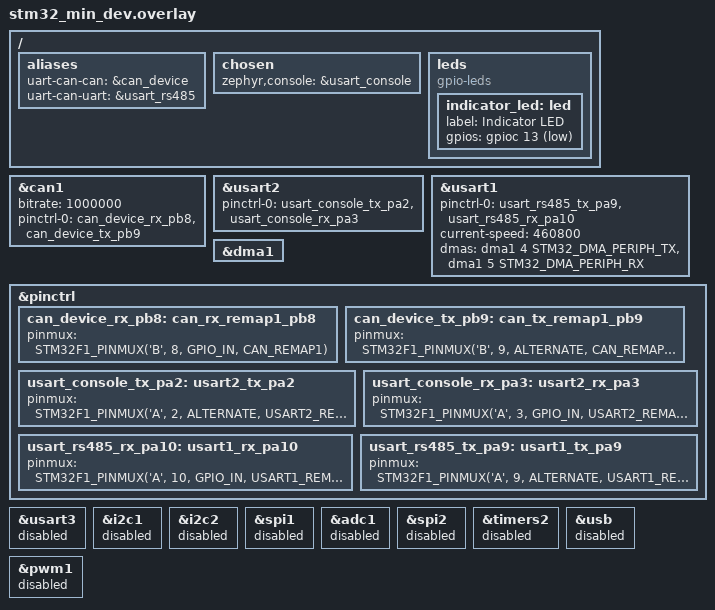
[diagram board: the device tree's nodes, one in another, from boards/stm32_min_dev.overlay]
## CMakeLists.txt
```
# SPDX-License-Identifier: Apache-2.0

cmake_minimum_required(VERSION 3.20.0)


find_package(Zephyr REQUIRED HINTS $ENV{ZEPHYR_BASE})
project(uart_to_can)

set(UART_TO_CAN_SRC
    ${CMAKE_CURRENT_SOURCE_DIR}/src/main.c
    ${CMAKE_CURRENT_SOURCE_DIR}/src/uart_to_can.c
    ${CMAKE_CURRENT_SOURCE_DIR}/src/uart_to_can_core_utility.c
)
target_sources(app PRIVATE ${UART_TO_CAN_SRC})
target_include_directories(app PRIVATE ${CMAKE_CURRENT_SOURCE_DIR}/include)
target_compile_options(app PRIVATE -Werror -Wall -Wextra -Wshadow -Wdouble-promotion -Wformat -Wunused)
target_link_libraries(app PRIVATE)
```

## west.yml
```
manifest:
  # lowest version of the manifest file schema that can parse this file’s data
  version: 1.2

  projects:
      - name: zephyr
        # instead of a tag, `revision` also supports hashes and branches. e.g., `--freeze` will
        # replace all revisions with their aactual commit hashes since tags can always be modified.
        revision: v4.4.0
        url: https://github.com/zephyrproject-rtos/zephyr
        # explicitly adding Zephyr-specific West extensions is only needed in case no `import`s are
        # used - which is almost never the case for Zephyr applications. with `import` in place,
        # the `west.yml` in Zephyr's repository takes care of adding the required West extensions.
        west-commands: scripts/west-commands.yml
        import:
          path-prefix: west_deps
        # # defaults to west.yml, but added for good measure/demonstration purposes.
        # file: west.yml
          name-allowlist:
            - cmsis
            - cmsis_6
            - hal_st
            - hal_stm32
            - hal_rpi_pico
```

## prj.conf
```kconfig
## Printing
# CONFIG_LOG=y
# # CONFIG_LOG_MODE_IMMEDIATE=y
# CONFIG_PRINTK=y
# CONFIG_LOG_DEFAULT_LEVEL=2

# CONFIG_THREAD_NAME=y
# CONFIG_ASSERT=y
# Peripherals

# UART
CONFIG_SERIAL=y
CONFIG_UART_ASYNC_API=y
CONFIG_UART_USE_RUNTIME_CONFIGURE=y

# CAN
CONFIG_CAN=y
CONFIG_CAN_STM32_BXCAN_MAX_STD_ID_FILTERS=4
CONFIG_CAN_STM32_BXCAN_MAX_EXT_ID_FILTERS=12

# Stacks size
CONFIG_ISR_STACK_SIZE=1024
CONFIG_MAIN_STACK_SIZE=2048
CONFIG_SYSTEM_WORKQUEUE_STACK_SIZE=4096

CONFIG_SYSTEM_WORKQUEUE_PRIORITY=-1

# CONFIG_KERNEL_MEM_POOL=y

# Debug options
# CONFIG_DEBUG_OPTIMIZATIONS=y
# CONFIG_NO_OPTIMIZATIONS=y
# CONFIG_BOOT_BANNER is not set
# CONFIG_EXCEPTION_DEBUG=y
CONFIG_STM32_ENABLE_DEBUG_SLEEP_STOP=y
```

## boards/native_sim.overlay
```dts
/ {
	aliases {
		uart-can-can = &can_device;
		uart-can-uart = &usart_rs485;
	};

	chosen{
		zephyr,console = &usart_console;

	};


	leds {
		compatible = "gpio-leds";
		status = "okay";
		indicator_led: indicator_led {
			label = "Indicator LED";
			gpios = <&gpio0 13 GPIO_ACTIVE_LOW>;
		};
	};
};

can_device: &can_loopback0 {
	status = "okay";
	bitrate = <250000>;
};

usart_console: &uart0 {
	status = "okay";
};


usart_rs485: &uart1 {
	status = "okay";
	current-speed = <115200>;
};
```

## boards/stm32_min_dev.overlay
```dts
/ {
	aliases {
		uart-can-can = &can_device;
		uart-can-uart = &usart_rs485;
	};

	chosen {
		zephyr,console = &usart_console;
	};

	leds {
		compatible = "gpio-leds";
		status = "okay";

		indicator_led: led {
			label = "Indicator LED";
			gpios = <&gpioc 13 GPIO_ACTIVE_LOW>;
		};
	};
};

can_device: &can1 {
	status = "okay";
	bitrate = <1000000>;
	pinctrl-0 = <&can_device_rx_pb8 &can_device_tx_pb9>;
	pinctrl-names = "default";
};

usart_console: &usart2 {
	status = "okay";
	pinctrl-0 = <&usart_console_tx_pa2 &usart_console_rx_pa3>;
	pinctrl-names = "default";
};

usart_rs485: &usart1 {
	status = "okay";
	pinctrl-0 = <&usart_rs485_tx_pa9 &usart_rs485_rx_pa10>;
	pinctrl-names = "default";
	current-speed = <460800>;
	/* Format: <&dma_controller_phandle channel channel_config> */
	dmas = <&dma1 4 STM32_DMA_PERIPH_TX>,  /* USART1_TX is fixed to Channel 4 */
	       <&dma1 5 STM32_DMA_PERIPH_RX>;  /* USART1_RX is fixed to Channel 5 */
	dma-names = "tx", "rx";
};

/* 1. Ensure the global DMA engine is turned on */
&dma1 {
	status = "okay";
};

&pinctrl {
	// swj-cfg = "full";

	can_device_rx_pb8: can_rx_remap1_pb8 {
		pinmux = <STM32F1_PINMUX('B', 8, GPIO_IN, CAN_REMAP1)>;
	};

	can_device_tx_pb9: can_tx_remap1_pb9 {
		pinmux = <STM32F1_PINMUX('B', 9, ALTERNATE, CAN_REMAP1)>;
	};

	usart_console_tx_pa2: usart2_tx_pa2 {
		pinmux = <STM32F1_PINMUX('A', 2, ALTERNATE, USART2_REMAP0)>;
	};

	usart_console_rx_pa3: usart2_rx_pa3 {
		pinmux = <STM32F1_PINMUX('A', 3, GPIO_IN, USART2_REMAP0)>;
	};

	usart_rs485_rx_pa10: usart1_rx_pa10 {
		pinmux = <STM32F1_PINMUX('A', 10, GPIO_IN, USART1_REMAP0)>;
	};

	usart_rs485_tx_pa9: usart1_tx_pa9 {
		pinmux = <STM32F1_PINMUX('A', 9, ALTERNATE, USART1_REMAP0)>;
	};
};


&usart3 {
	status = "disabled";
};

&i2c1 {
	status = "disabled";
};

&i2c2 {
	status = "disabled";
};

&spi1 {
	status = "disabled";
};

&adc1 {
	status = "disabled";
};

&spi2 {
	status = "disabled";
};

&timers2 {
	status = "disabled";
};

&usb {
	status = "disabled";
};

&pwm1 {
	status = "disabled";
};
```

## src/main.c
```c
#include "uart_to_can.h"

#include <zephyr/device.h>
#include <zephyr/devicetree.h>
#include <zephyr/drivers/can.h>
#include <zephyr/drivers/gpio.h>
#include <zephyr/kernel.h>
#include <zephyr/logging/log.h>

#include <zephyr/drivers/uart.h>

LOG_MODULE_REGISTER(main, LOG_LEVEL_INF);

#define LED0_NODE DT_ALIAS(led0)
static const struct gpio_dt_spec led = GPIO_DT_SPEC_GET(LED0_NODE, gpios);
int main(void)
{

  int err;
  err = init_uart_to_can();
  if (err < 0)
  {
    LOG_ERR("Failed to init uart to can");
    return 0;
  }

  if (!gpio_is_ready_dt(&led))
  {
    LOG_ERR("LED not ready");
  }

  err = gpio_pin_configure_dt(&led, GPIO_OUTPUT_ACTIVE);
  if (err < 0)
  {
    LOG_WRN("Failed to indicator LED");
  }

  while (1)
  {

    err = gpio_pin_toggle_dt(&led);
    k_msleep(2000);
  }
}
```

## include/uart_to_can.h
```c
#ifndef __UART_TO_CAN_H__
#define __UART_TO_CAN_H__

#include <stddef.h>
#include <stdint.h>
#include <zephyr/device.h>
#include <zephyr/drivers/uart.h>

#include "uart_to_can_core_utility.h"
/* Enum definition from supported commands. */
enum UART_CAN_COMMANDS
{
  UART_CAN_COMMANDS_START_CAN = 'O',
  UART_CAN_COMMANDS_STOP_CAN = 'C',
  UART_CAN_COMMANDS_SET_BITRATE = 'S',
  UART_CAN_COMMANDS_SEND_11_BIT_CAN = 't',
  UART_CAN_COMMANDS_SEND_29_BIT_CAN = 'T',
  UART_CAN_COMMANDS_VERSION = 'V',
  UART_CAN_COMMANDS_HELP = 'h',
  UART_CAN_COMMANDS_RESET = 'L',
  UART_CAN_COMMANDS_GET_STATE = 'G',
  UART_CAN_COMMANDS_ADD_FILTER_11_BIT = 'm',
  UART_CAN_COMMANDS_ADD_FILTER_29_BIT = 'M',
  UART_CAN_COMMANDS_REMOVE_FILTER = 'f',
  UART_CAN_COMMANDS_REMOVE_ALL_FILTERS = 'F',
};

/**
 * @brief Initialize the UART to CAN module.
 *
 * @return 0 if successful, <0 on error.
 */
int init_uart_to_can(void);
#endif /* __UART_TO_CAN_H__ */
```

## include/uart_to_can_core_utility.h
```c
#ifndef __UART_TO_CAN_CORE_UTILITY_H__
#define __UART_TO_CAN_CORE_UTILITY_H__

#include <assert.h>
#include <stdlib.h>
#include <stdio.h>
#include <zephyr/device.h>
#include <zephyr/drivers/can.h>
#include <zephyr/sys/ring_buffer.h>

#define HARDWARE_VERSION_MAJOR 0
#define HARDWARE_VERSION_MINOR 1

#define SOFTWARE_VERSION_MAJOR 0
#define SOFTWARE_VERSION_MINOR 1

#define CAN_ID_11_BIT_BYTE_LENGHT 3
#define CAN_ID_29_BIT_BYTE_LENGHT 8
#define CAN_FILTER_BYTE_LENGHT (8 + 8)
#define MESSAGE_BASE 16
#define COMMAND_RESPONSE_OKAY "\r"
#define COMMAND_RESPONSE_ERROR "\a"

#define FULL_VERSION_RESPONSE       \
  STRINGIFY(HARDWARE_VERSION_MAJOR) \
  STRINGIFY(HARDWARE_VERSION_MINOR) \
  STRINGIFY(SOFTWARE_VERSION_MAJOR) \
  STRINGIFY(SOFTWARE_VERSION_MINOR) \
  COMMAND_RESPONSE_OKAY

#define MAX_UART_CAN_FRAME \
  (1 + CAN_ID_29_BIT_BYTE_LENGHT + 2 + 1 + CAN_MAX_DLEN * 2 + 1)

#if defined(CONFIG_CAN_STM32_BXCAN_MAX_STD_ID_FILTERS)
#define CONFIG_CAN_MAX_STD_ID_FILTERS CONFIG_CAN_STM32_BXCAN_MAX_STD_ID_FILTERS
#else
#define CONFIG_CAN_MAX_STD_ID_FILTERS 5
#endif

#if defined(CONFIG_CAN_STM32_BXCAN_MAX_EXT_ID_FILTERS)
#define CONFIG_CAN_MAX_EXT_ID_FILTERS CONFIG_CAN_STM32_BXCAN_MAX_EXT_ID_FILTERS
#else
#define CONFIG_CAN_MAX_EXT_ID_FILTERS 5
#endif

struct uart_message
{
  void *fifo_reserved; /* 1st word reserved for use by FIFO */
  uint8_t buffer[MAX_UART_CAN_FRAME];
  size_t buffer_size;
};

static inline struct uart_message string_to_uart_message(const char *string)
{
  struct uart_message uart_message;
  uart_message.buffer_size = strlen(string);
  assert((size_t)snprintf(uart_message.buffer, MAX_UART_CAN_FRAME, "%s",
                          string) == uart_message.buffer_size);
  return uart_message;
}

/**
 * @brief Return the next byte in the ring buffer, this function assume that you
 * are sure that data is in the buffer, it asserts if the buffer is empty
 * @param buf Pointer to the ring buffer
 * @return the next byte in the ring buffer
 */
static inline uint8_t ring_buf_get_char(struct ring_buf *buf)
{
  uint8_t data;
  assert(ring_buf_get(buf, &data, 1) == 1);
  return data;
}

static inline bool ring_buf_get_char_to_uint(struct ring_buf *buf,
                                             uint8_t num_of_bytes, int base,
                                             unsigned long *out_val)
{
  char data[num_of_bytes + 1];
  char *temp_data;
  unsigned long temp_val;
  for (uint32_t i = 0; i < num_of_bytes; i++)
  {
    data[i] = ring_buf_get_char(buf);
  }
  data[num_of_bytes] = '\0';
  temp_val = strtoul(data, &temp_data, base);

  if ((uintptr_t)temp_data != (uintptr_t)data)
  {
    *out_val = temp_val;
    return true;
  }
  return false;
}

static inline bool ring_buf_get_hex_to_uint8_t(struct ring_buf *buf,
                                               uint8_t *out_val)
{
  char data[2 + 1];
  char *temp_data;
  unsigned long temp_val;
  for (uint32_t i = 0; i < 2; i++)
  {
    data[i] = ring_buf_get_char(buf);
  }
  data[2] = '\0';
  temp_val = strtoul(data, &temp_data, 16);

  if ((uintptr_t)temp_data != (uintptr_t)data)
  {
    *out_val = temp_val;
    return true;
  }
  return false;
}

static inline bool ring_buf_get_hex_to_uint32_t(struct ring_buf *buf,
                                                uint32_t *out_val)
{
  char data[8 + 1];
  char *temp_data;
  unsigned long temp_val;
  for (uint32_t i = 0; i < 8; i++)
  {
    data[i] = ring_buf_get_char(buf);
  }
  data[8] = '\0';
  temp_val = strtoul(data, &temp_data, 16);

  if ((uintptr_t)temp_data != (uintptr_t)data)
  {
    *out_val = temp_val;
    return true;
  }
  return false;
}
/**
 * @brief Checks if the ring buffer has wrapped
 *
 * @param buf Pointer to the ring buffer
 * @return true if the ring buffer has wrapped, false otherwise
 */
bool ring_buf_has_wrapped(struct ring_buf *buf);

/**
 * @brief Starts the CAN device
 *
 * @param can_dev Pointer to the CAN device
 * @return 0 on success, negative error code on failure
 */
int start_can_device(const struct device *can_dev);

/**
 * @brief Stops the CAN device
 *
 * @param can_dev Pointer to the CAN device
 * @return 0 on success, negative error code on failure
 */
int stop_can_device(const struct device *can_dev);

/**
 * @brief Sets the bitrate for the CAN device
 *
 * @param can_dev Pointer to the CAN device
 * @param bitrate_code uint8_t the encoded value of the bitrate
 * @return 0 on success, negative error code on failure
 */
int set_bitrate(const struct device *can_dev, uint8_t bitrate_code);

/**
 * @brief Adds a filter to the CAN device
 *
 * @param can_dev Pointer to the CAN device
 * @param filter_id The filter ID
 * @param filter_mask The filter mask
 * @param is_extended_id Whether the filter is for an extended ID
 * @return 0 on success, negative error code on failure
 */
int add_can_filter(const struct device *can_dev, uint32_t filter_id,
                   uint32_t filter_mask, bool is_extended_id);

/**
 * @brief Sends a message to the CAN bus
 *
 * @param can_dev Pointer to the CAN device
 * @param addr The CAN ID of the message
 * @param data Pointer to the data to send
 * @param data_size The size of the data to send
 * @param is_extended_id Whether the message is an extended ID
 * @param is_rtr Whether the message is an remote data
 * @return true if the message was sent successfully, false otherwise
 */
int send_can_message_no_wait(const struct device *can_dev, uint32_t addr,
                             const uint8_t data[], uint8_t data_size,
                             bool is_extended_id, bool is_rtr);

/**
 * @brief Searches for '\r' in the ring buffer, considering wrap-around
 *
 * @param buf Pointer to the ring buffer
 * @return The index of '\r' if found (positive index) or if wrap around
 *         occured (negative index), INT_MIN otherwise
 */
int search_r_consider_wrap(struct ring_buf *buf);

int send_command_status_via_uart(struct uart_message *message);

/**
@breif Clear all the character in a ring buffer before the char '\r' and if no
'\r', it clears the whole buffer
*/
void clear_buf_till_r(struct ring_buf *buf);

/**
 * @brief Converts a CAN frame to a uart message
 *
 * @param frame The CAN frame to convert
 * @return The uart message
 */
struct uart_message can_frame_to_uart_message(const struct can_frame *frame, int filter_id);
int remove_can_filter(const struct device *can_dev, int filter_id);
#endif /* __UART_TO_CAN_CORE_UTILITY_H__ */
```

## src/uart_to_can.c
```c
#include "uart_to_can.h"

#include "zephyr/sys/__assert.h"
#include "zephyr/sys/ring_buffer.h"
#include "zephyr/toolchain.h"
#include <stdbool.h>
#include <stddef.h>
#include <stdint.h>
#include <stdio.h>
#include <string.h>
#include <zephyr/device.h>
#include <zephyr/devicetree.h>
#include <zephyr/drivers/can.h>
#include <zephyr/drivers/gpio.h>
#include <zephyr/kernel.h>
#include <zephyr/logging/log.h>

#include <zephyr/drivers/uart.h>

#include "uart_to_can_core_utility.h"

#ifdef CONFIG_ZTEST
#define CONFIG_UART_TO_CAN_STATIC
#else
#define CONFIG_UART_TO_CAN_STATIC static
#endif

LOG_MODULE_REGISTER(uart_to_can, LOG_LEVEL_INF);

#define CAN_NODE DT_ALIAS(uart_can_can)
static const struct device *can_dev = DEVICE_DT_GET(CAN_NODE);

#define UART_NODE DT_ALIAS(uart_can_uart)
static const struct device *uart_dev = DEVICE_DT_GET(UART_NODE);

// int filter_ids_std[CONFIG_CAN_MAX_STD_ID_FILTERS];
// int filter_ids_ext[CONFIG_CAN_MAX_EXT_ID_FILTERS];

#define DMA_BUF_SIZE 32
#define RX_BUF_SIZE 1024
/* 2. Declare Memory Buffers */
static uint8_t dma_buf_a[DMA_BUF_SIZE];
static uint8_t dma_buf_b[DMA_BUF_SIZE];

struct UartProcessWork
{
  struct k_work work;
  bool buffer_overflowed;
};

static struct UartProcessWork uart_process_work;

K_MEM_SLAB_DEFINE(filter_id_list_slab, sizeof(int),
                  CONFIG_CAN_MAX_STD_ID_FILTERS + CONFIG_CAN_MAX_EXT_ID_FILTERS,
                  4);

int *filter_ids_ptr_map[CONFIG_CAN_MAX_STD_ID_FILTERS +
                        CONFIG_CAN_MAX_EXT_ID_FILTERS];

RING_BUF_DECLARE(rx_ring_buffer, RX_BUF_SIZE);

K_MEM_SLAB_DEFINE(uart_message_slab, sizeof(struct uart_message), 15, 4);
K_FIFO_DEFINE(uart_message_fifo);

int send_command_status_via_uart_handle_fifo(struct uart_message *message);

static void uart_rx_reset_buffer_timer_fn(struct k_timer *timer_id)
{
  ARG_UNUSED(timer_id);
  // Resetting the buffer is allowed here becasue only unprocessed command will
  // be in the buffer at this point.
  if (ring_buf_size_get(&rx_ring_buffer) > 0)
  {
    LOG_INF("Resetting buffer size: %d", ring_buf_size_get(&rx_ring_buffer));
    ring_buf_reset(&rx_ring_buffer);
  }
}
K_TIMER_DEFINE(uart_rx_reset_buffer_timer, uart_rx_reset_buffer_timer_fn, NULL);

CONFIG_UART_TO_CAN_STATIC int
parse_and_send_can_message_no_wait(struct ring_buf *const buf,
                                   const uint32_t can_id, bool is_extended_id)
{
  int err;
  unsigned long temp_long;
  uint8_t dlc;
  uint8_t can_data[8];
  if (ring_buf_size_get(buf) < 1)
  {
    err = -1;
    LOG_ERR("Not enough data in buffer");
    goto parse_and_send_can_message_no_wait_11bit_return;
  }
  if (ring_buf_get_char_to_uint(buf, 1, 16, &temp_long))
  {
    dlc = temp_long;
  }
  else
  {
    err = -1;
    LOG_ERR("Invalid dlc");
    goto parse_and_send_can_message_no_wait_11bit_return;
  }
  if (ring_buf_size_get(buf) < 2 * dlc)
  {
    err = -1;
    LOG_ERR("Not enough data in buffer");
    goto parse_and_send_can_message_no_wait_11bit_return;
  }
  for (uint32_t i = 0; i < dlc; i++)
  {
    if (!ring_buf_get_hex_to_uint8_t(buf, &can_data[i]))
    {
      err = -1;
      LOG_ERR("Invalid data");
      goto parse_and_send_can_message_no_wait_11bit_return;
    }
  }
  err = send_can_message_no_wait(can_dev, can_id, can_data, dlc, is_extended_id,
                                 false);
parse_and_send_can_message_no_wait_11bit_return:
  return err;
}

CONFIG_UART_TO_CAN_STATIC int
parse_and_send_can_message_no_wait_11bit(struct ring_buf *const buf)
{
  int err = 0;
  unsigned long temp_long;
  uint16_t can_id = 0;
  // First 1 for dlc
  if (ring_buf_size_get(buf) < (CAN_ID_11_BIT_BYTE_LENGHT + 1))
  {
    err = -1;
    LOG_ERR("Not enough data in buffer");
    goto parse_and_send_can_message_no_wait_11bit_return;
  }
  if (ring_buf_get_char_to_uint(buf, CAN_ID_11_BIT_BYTE_LENGHT, MESSAGE_BASE,
                                &temp_long))
  {
    can_id = temp_long;
  }
  else
  {
    err = -1;
    LOG_ERR("Invalid CAN ID");
    goto parse_and_send_can_message_no_wait_11bit_return;
  }
  err = parse_and_send_can_message_no_wait(buf, can_id, false);
parse_and_send_can_message_no_wait_11bit_return:
  return err;
}

CONFIG_UART_TO_CAN_STATIC int
parse_and_send_can_message_no_wait_29bit(struct ring_buf *const buf)
{
  int err = 0;
  unsigned long temp_long;
  uint32_t can_id = 0;
  // First 1 for dlc
  if (ring_buf_size_get(buf) < (CAN_ID_29_BIT_BYTE_LENGHT + 1))
  {
    err = -1;
    LOG_ERR("Not enough data in buffer");
    goto parse_and_send_can_message_no_wait_11bit_return;
  }
  if (ring_buf_get_char_to_uint(buf, CAN_ID_29_BIT_BYTE_LENGHT, MESSAGE_BASE,
                                &temp_long))
  {
    can_id = temp_long;
  }
  else
  {
    err = -1;
    LOG_ERR("Invalid CAN ID");
    goto parse_and_send_can_message_no_wait_11bit_return;
  }
  err = parse_and_send_can_message_no_wait(buf, can_id, true);
parse_and_send_can_message_no_wait_11bit_return:
  return err;
}

CONFIG_UART_TO_CAN_STATIC int
parse_and_add_can_filter(struct ring_buf *const buf, bool is_extended_id)
{
  int err = 0;
  uint32_t filter_id;
  uint32_t filter_mask;
  int a = ring_buf_size_get(buf);
  ARG_UNUSED(a);
  if (ring_buf_size_get(buf) < (CAN_FILTER_BYTE_LENGHT))
  {
    err = -1;
    LOG_ERR("Not enough data in buffer %d", a);
    goto parse_and_send_can_message_no_wait_11bit_return;
  }
  if (!ring_buf_get_hex_to_uint32_t(buf, &filter_id))
  {
    err = -1;
    LOG_ERR("Invalid CAN Filter ID");
    goto parse_and_send_can_message_no_wait_11bit_return;
  }
  if (!ring_buf_get_hex_to_uint32_t(buf, &filter_mask))
  {
    err = -1;
    LOG_ERR("Invalid CAN Filter mask");
    goto parse_and_send_can_message_no_wait_11bit_return;
  }
  err = add_can_filter(can_dev, filter_id, filter_mask, is_extended_id);
parse_and_send_can_message_no_wait_11bit_return:
  return err;
}

CONFIG_UART_TO_CAN_STATIC int
parse_and_add_can_filter_11bit(struct ring_buf *const buf)
{
  return parse_and_add_can_filter(buf, false);
}

CONFIG_UART_TO_CAN_STATIC int
parse_and_add_can_filter_29bit(struct ring_buf *const buf)
{
  return parse_and_add_can_filter(buf, true);
}

CONFIG_UART_TO_CAN_STATIC int
send_can_message_to_uart(const struct can_frame *frame, int filter_id)
{
  struct uart_message message = can_frame_to_uart_message(frame, filter_id);

  return send_command_status_via_uart(&message);
}

CONFIG_UART_TO_CAN_STATIC int
parse_and_remove_can_filter(struct ring_buf *const buf)
{
  int err = 0;
  unsigned long temp_long;
  uint8_t filter_id;
  if (ring_buf_size_get(buf) < 3)
  {
    err = -1;
    LOG_ERR("");
    goto parse_and_remove_can_filter_return;
  }

  if (ring_buf_get_char_to_uint(buf, 2, 16, &temp_long))
  {
    filter_id = temp_long;
  }
  else
  {
    err = -1;
    LOG_ERR("Invalid Filter ID");
    goto parse_and_remove_can_filter_return;
  }
  err = remove_can_filter(can_dev, filter_id);
parse_and_remove_can_filter_return:
  return err;
}

CONFIG_UART_TO_CAN_STATIC int remove_all_can_filters()
{
  int err = 0;
  for (int i = 0;
       i < CONFIG_CAN_MAX_STD_ID_FILTERS + CONFIG_CAN_MAX_EXT_ID_FILTERS; i++)
  {
    remove_can_filter(can_dev, i);
  }
  // int max_filters = can_get_max_filters(can_dev, false);
  // for (int i = 0; i < max_filters; i++) {
  //   can_remove_rx_filter(can_dev, i);
  // }
  // max_filters = can_get_max_filters(can_dev, true);
  // for (int i = 0; i < max_filters; i++) {
  //   can_remove_rx_filter(can_dev, i);
  // }
  return err;
}

CONFIG_UART_TO_CAN_STATIC int
parse_and_remove_all_can_filters(struct ring_buf *const buf)
{
  int err = 0;
  if (ring_buf_size_get(buf) < 1)
  {
    err = -1;
    LOG_ERR("");
    goto parse_and_remove_all_can_filters_return;
  }
  err = remove_all_can_filters();
parse_and_remove_all_can_filters_return:
  return err;
}

CONFIG_UART_TO_CAN_STATIC void send_command_response(int err,
                                                     char command_char)
{
  struct uart_message uart_message;

  uart_message.buffer[0] = command_char;
  err = snprintf(&uart_message.buffer[1], 3, "%02x", (uint8_t)((err) & 0xFF));
  __ASSERT(err == 2, "Error formatting error code");
  uart_message.buffer[3] = COMMAND_RESPONSE_OKAY[0];
  uart_message.buffer_size = 4;

  err = send_command_status_via_uart(&uart_message);
}

void can_rx_callback(const struct device *dev, struct can_frame *frame,
                     void *user_data)
{
  (void)user_data;
  int filter_id = *(int *)user_data;
  LOG_INF("Received CAN Frame from device %s! ID: 0x%03x, DLC: %d", dev->name,
          frame->id, frame->dlc);
  /* Safely print the incoming data payload using the hex helper */
  LOG_HEXDUMP_DBG(frame->data, frame->dlc, "Payload:");
  // k_msgq_put(&can_data_msgq, frame, K_NO_WAIT);
  send_can_message_to_uart(frame, filter_id);
}

void can_tx_callback(__maybe_unused const struct device *dev, int err,
                     void *user_data)
{
  char *sender = (char *)user_data;

  if (err != 0)
  {
    LOG_ERR("Sending failed from %s with [%d]", sender, err);
  }
  else
  {
    LOG_DBG("Sent succuss from %s with [%d]", sender, err);
  }
  send_command_response(err, sender[0]);
}

CONFIG_UART_TO_CAN_STATIC int send_version()
{
  struct uart_message message;

  snprintf(message.buffer, MAX_UART_CAN_FRAME, "%s", FULL_VERSION_RESPONSE);
  message.buffer_size = strlen(FULL_VERSION_RESPONSE) + 1;
  return send_command_status_via_uart(&message);
}

// CONFIG_UART_TO_CAN_STATIC int can_state_command() {
//   int err = 0;
//   struct uart_message message;
//   const char *command_response;
//   enum can_state state;
//   struct can_bus_err_cnt err_cnt;

//   err = can_get_state(can_dev, &state, &err_cnt);
//   if (err != 0) {
//     LOG_ERR("Error getting CAN state: %d", err);
//     goto reset_command_return;
//   }
//   switch (state) {
//   case CAN_STATE_ERROR_ACTIVE:
//     command_response = "A";
//     break;
//   case CAN_STATE_ERROR_WARNING:
//     command_response = "W";
//     break;
//   case CAN_STATE_ERROR_PASSIVE:
//     command_response = "P";
//     break;
//   case CAN_STATE_BUS_OFF:
//     command_response = "O";
//     break;
//   case CAN_STATE_STOPPED:
//     command_response = "S";
//     break;
//   default:
//     command_response = "U";
//     break;
//   }
//   message.buffer_size = strlen(command_response);
//   memcpy(message.buffer, command_response, message.buffer_size);
//   return send_command_status_via_uart(&message);
// reset_command_return:
//   return err;
// }

CONFIG_UART_TO_CAN_STATIC int reset_command()
{
  int err;
  enum can_state state;
  struct can_bus_err_cnt err_cnt;
  err = uart_tx_abort(uart_dev);
  if (err != 0)
  {
    LOG_ERR("Error abort UART TX: %d", err);
  }
  err = can_get_state(can_dev, &state, &err_cnt);
  if (err != 0)
  {
    LOG_ERR("Error getting CAN state: %d", err);
    goto reset_command_return;
  }
  if (state != CAN_STATE_STOPPED)
  {
    err = can_stop(can_dev);
    if (err != 0)
    {
      LOG_ERR("Error stopping CAN: %d", err);
      goto reset_command_return;
    }
  }
  remove_all_can_filters();

reset_command_return:
  return err;
}

CONFIG_UART_TO_CAN_STATIC void
print_buffer_without_clearing(struct ring_buf *buf)
{
  if (IS_ENABLED(CONFIG_LOG))
  {
    uint8_t buffer[500];
    size_t bytes_read = ring_buf_peek(buf, buffer, 500);
    LOG_INF("Buffer space: %d, Buffer size: %d", ring_buf_space_get(buf),
            ring_buf_size_get(buf));
    LOG_INF("Buffer space: %d, Buffer size: %d", ring_buf_space_get(buf),
            ring_buf_size_get(buf));
    LOG_HEXDUMP_INF(buffer, bytes_read, "Dumping recieve buffer:");
  }
}

// CONFIG_UART_TO_CAN_STATIC void
// send_command_add_filter_response(int filter_id, char command_char) {
//   struct uart_message uart_message;
//   uart_message.buffer[0] = command_char;

//   __ASSERT(snprintf(&uart_message.buffer[1], 3, "%02x",
//                     filter_id < 0 ? 0 : filter_id) == 2,
//            "Error formatting filter id");
//   uart_message.buffer[3] =
//       filter_id < 0 ? COMMAND_RESPONSE_ERROR[0] : COMMAND_RESPONSE_OKAY[0];
//   uart_message.buffer_size = 4;
//   send_command_status_via_uart(&uart_message);
// }

/**
 * @brief Processes data from the UART ring buffer
 *
 * @param buf Pointer to the ring buffer
 */
CONFIG_UART_TO_CAN_STATIC void
process_and_clear_command_data_uart_data(struct ring_buf *buf)
{
  int err = -1;
  while (search_r_consider_wrap(buf) != INT_MIN)
  {
    print_buffer_without_clearing(buf);
    enum UART_CAN_COMMANDS command = ring_buf_get_char(buf);
    switch (command)
    {

    case UART_CAN_COMMANDS_START_CAN:
      LOG_INF("Starting CAN");
      err = start_can_device(can_dev);
      send_command_response(err, command);
      break;
    case UART_CAN_COMMANDS_STOP_CAN:
      LOG_INF("Stopping CAN");
      err = stop_can_device(can_dev);
      send_command_response(err, command);
      break;
    case UART_CAN_COMMANDS_SET_BITRATE:
      LOG_INF("Setting CAN Bitrate");
      err = set_bitrate(can_dev, ring_buf_get_char(buf));
      send_command_response(err, command);
      break;
    // case 's':
    //   // TODO (Matthew)
    //   break;
    case UART_CAN_COMMANDS_SEND_11_BIT_CAN:
      LOG_INF("Send data to standard 11 bit CAN");
      err = parse_and_send_can_message_no_wait_11bit(buf);
      // if err then there is not enough space in the can_tx_mail_box and the issue is from the driver and the driver should clear it callback mailbox
      if (err != 0)
      {
        LOG_ERR("Failed to send CAN message: %d", err);
        err = -EPERM;
        send_command_response(err, command);
      }
      break;
    case UART_CAN_COMMANDS_SEND_29_BIT_CAN:
      LOG_INF("Send data to standard 29 bit CAN");
      err = parse_and_send_can_message_no_wait_29bit(buf);
      if (err != 0)
      {
        LOG_ERR("Failed to send CAN message: %d", err);
        err = -EPERM;
        send_command_response(err, command);
      }
      break;
    case UART_CAN_COMMANDS_VERSION:
      LOG_INF("Version");
      err = send_version(uart_dev);
      break;
    case UART_CAN_COMMANDS_HELP:
      LOG_INF("Help");
      // TODO (Matthew)
      break;
    case UART_CAN_COMMANDS_RESET:
      LOG_INF("Reset");
      err = reset_command();
      send_command_response(err, command);
      break;

    case UART_CAN_COMMANDS_GET_STATE:
      LOG_INF("Getting State");
      break;
    case UART_CAN_COMMANDS_ADD_FILTER_11_BIT:
      LOG_INF("Adding standard filter");
      err = parse_and_add_can_filter_11bit(buf);
      send_command_response(err, command);
      break;
    case UART_CAN_COMMANDS_ADD_FILTER_29_BIT:
      LOG_INF("Adding extended filter");
      err = parse_and_add_can_filter_29bit(buf);
      send_command_response(err, command);
      break;
    case UART_CAN_COMMANDS_REMOVE_FILTER:
      LOG_INF("Removing filter");
      err = parse_and_remove_can_filter(buf);
      send_command_response(err, command);
      break;
    case UART_CAN_COMMANDS_REMOVE_ALL_FILTERS:
      LOG_INF("Removing all filters");
      err = parse_and_remove_all_can_filters(buf);
      send_command_response(err, command);
      break;
    default:
      LOG_ERR("Unrecongnised command");
      err = -ENOENT;
      send_command_response(err, command);
      break;
    }
    clear_buf_till_r(buf);
  }
}

int copy_data_to_ring_buf(struct ring_buf *ring_buf, const uint8_t *data,
                          size_t data_len)
{
  size_t total_written = 0;

  while (total_written < data_len)
  {
    uint8_t *dst = NULL;
    uint32_t claimed = ring_buf_put_claim(ring_buf, &dst, data_len - total_written);

    if (claimed == 0)
    {
      break;
    }

    memcpy(dst, &data[total_written], claimed);

    if (ring_buf_put_finish(ring_buf, claimed) != 0)
    {
      return -1;
    }

    total_written += claimed;
  }

  return total_written == data_len ? (int)total_written : -ENOSPC;
}

void uart_process_work_handler(struct k_work *work)
{
  struct UartProcessWork *process_work =
      CONTAINER_OF(work, struct UartProcessWork, work);
  LOG_DBG("process_and_clear_command_data_uart_data");
  // Perform complete commands possible
  process_and_clear_command_data_uart_data(&rx_ring_buffer);
  // clear command that might have possible values dropped.
  if (process_work->buffer_overflowed)
  {
    LOG_ERR("Ring buffer full! Dropping remaining bytes");
    clear_buf_till_r(&rx_ring_buffer);
    LOG_INF("Clearing ring buffer");
    // TODO (Matthew): Send error
  }
  k_timer_start(&uart_rx_reset_buffer_timer, K_MSEC(1000), K_NO_WAIT);
}

CONFIG_UART_TO_CAN_STATIC void uart_cb(const struct device *dev,
                                       __maybe_unused struct uart_event *evt,
                                       __maybe_unused void *user_data)
{
  switch (evt->type)
  {
  case UART_TX_ABORTED:
    LOG_DBG("UART event UART_TX_ABORTED type: %d\n", evt->type);
    [[fallthrough]];
  case UART_TX_DONE:
    LOG_DBG("UART event UART_TX_DONE type: %d\n", evt->type);
    struct uart_message *msg =
        CONTAINER_OF((void *)(evt->data.tx.buf), struct uart_message, buffer);
    k_mem_slab_free(&uart_message_slab, (void *)msg);

    struct uart_message *msg_new =
        (struct uart_message *)k_fifo_get(&uart_message_fifo, K_NO_WAIT);
    if (msg_new != NULL)
    {
      LOG_INF("Backlogged message wait to be sent");
      send_command_status_via_uart_handle_fifo(msg_new);
    }
    break;

  case UART_RX_RDY:
    LOG_DBG("UART event UART_RX_RDY type: %d\n", evt->type);
    int bytes_copied = copy_data_to_ring_buf(&rx_ring_buffer,
                                             &evt->data.rx.buf[evt->data.rx.offset],
                                             evt->data.rx.len);
    if (bytes_copied != (int)evt->data.rx.len)
    {
      LOG_ERR("RX overflow: copied %d of %d bytes", bytes_copied, evt->data.rx.len);
      uart_process_work.buffer_overflowed = true;
    }
    k_work_submit(&uart_process_work.work);

    break;

  case UART_RX_BUF_REQUEST:
    LOG_DBG("UART event UART_RX_BUF_REQUEST type: %d\n", evt->type);

    if (evt->data.rx_buf.buf == dma_buf_a)
    {
      uart_rx_buf_rsp(dev, dma_buf_b, DMA_BUF_SIZE);
    }
    else
    {
      uart_rx_buf_rsp(dev, dma_buf_a, DMA_BUF_SIZE);
    }

    break;

  case UART_RX_BUF_RELEASED:
    LOG_DBG("UART event UART_RX_BUF_RELEASED type: %d\n", evt->type);
    break;

  case UART_RX_DISABLED:
    LOG_DBG("UART event UART_RX_DISABLED type: %d\n", evt->type);
    break;

  case UART_RX_STOPPED:
    LOG_DBG("UART event UART_RX_STOPPED type: %d\n", evt->type);
    break;

  default:
    break;
  }
}

int init_uart_to_can(void)
{
  int err = 0;
  if (!device_is_ready(uart_dev))
  {
    LOG_ERR("UART device not ready yet!");
    return -EIO;
  }

  if (!device_is_ready(can_dev))
  {
    LOG_ERR("CAN device not ready yet!");
    return -EIO;
  }

  /* Register the async interrupt handler */
  err = uart_callback_set(uart_dev, uart_cb, (void *)uart_dev);

  if (err)
  {
    LOG_ERR("Failed to register UART callback (err %d)", err);
    return err;
  }

  err = uart_rx_enable(uart_dev, dma_buf_a, DMA_BUF_SIZE, 20);
  if (err)
  {
    LOG_ERR("Failed to enable UART reception (err %d)", err);
    return err;
  }

  for (size_t i = 0;
       i < (CONFIG_CAN_MAX_STD_ID_FILTERS + CONFIG_CAN_MAX_EXT_ID_FILTERS);
       i++)
  {
    filter_ids_ptr_map[i] = NULL;
  }

  k_work_init(&uart_process_work.work, uart_process_work_handler);

  return err;
}

int send_command_status_via_uart_handle_fifo(struct uart_message *message)
{
  int err;

  err = uart_tx(uart_dev, message->buffer, message->buffer_size,
                500 * message->buffer_size);
  if (err == -EBUSY)
  {
    k_fifo_put(&uart_message_fifo, message);
    err = 0;
  }
  return err;
}

int send_command_status_via_uart(struct uart_message *message)
{
  struct uart_message *block_ptr;
  int err;
  err = k_mem_slab_alloc(&uart_message_slab, (void **)&block_ptr, K_NO_WAIT);

  if (err != 0)
  {
    LOG_ERR("Failed to get memory from slab");
    goto send_command_status_via_uart_return;
  }

  block_ptr->buffer_size = message->buffer_size;
  memcpy(block_ptr->buffer, message->buffer, message->buffer_size);

  LOG_INF("Sending uart message with len %d", block_ptr->buffer_size);

  LOG_HEXDUMP_INF(block_ptr->buffer, block_ptr->buffer_size, "Data");

  err = send_command_status_via_uart_handle_fifo(block_ptr);
  if (err < 0)
  {
    LOG_ERR("Failed to add message to UART msgq");
    k_mem_slab_free(&uart_message_slab, (void *)block_ptr);
    goto send_command_status_via_uart_return;
  }
send_command_status_via_uart_return:
  return err;
}
```

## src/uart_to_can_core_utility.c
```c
#include "uart_to_can_core_utility.h"

#include "zephyr/sys/ring_buffer.h"
#include "zephyr/toolchain.h"
#include <stddef.h>
#include <stdint.h>
#include <stdio.h>
#include <string.h>
#include <zephyr/device.h>
#include <zephyr/devicetree.h>
#include <zephyr/drivers/can.h>
#include <zephyr/drivers/gpio.h>
#include <zephyr/kernel.h>
#include <zephyr/logging/log.h>

#include <zephyr/drivers/uart.h>

#ifdef CONFIG_ZTEST
#define CONFIG_UART_TO_CAN_STATIC
#else
#define CONFIG_UART_TO_CAN_STATIC static
#endif

LOG_MODULE_REGISTER(uart_to_can_core_utility, LOG_LEVEL_INF);

extern struct k_mem_slab filter_id_list_slab;
extern int *filter_ids_ptr_map[CONFIG_CAN_MAX_STD_ID_FILTERS +
                               CONFIG_CAN_MAX_EXT_ID_FILTERS];

void can_rx_callback(const struct device *dev, struct can_frame *frame,
                     void *user_data);

void can_tx_callback(__maybe_unused const struct device *dev, int err,
                     void *user_data);

bool ring_buf_has_wrapped(struct ring_buf *buf)
{
  uint32_t free_space = ring_buf_size_get(buf);
  uint8_t *data;
  uint32_t claim_size = ring_buf_get_claim(buf, &data, free_space);
  int err = ring_buf_get_finish(buf, 0);
  __ASSERT(err == 0, "Failed to free ring buffer");
  ARG_UNUSED(err);
  return claim_size < free_space;
}

int search_r_consider_wrap(struct ring_buf *buf)
{

  uint8_t *data;
  uint8_t *data_remain;
  bool buf_has_wrapped = ring_buf_has_wrapped(buf);
  uint32_t get_size = ring_buf_size_get(buf);
  uint32_t get_claim_size = ring_buf_get_claim(buf, &data, get_size);
  int ret_val = INT_MIN;
  for (uint32_t i = 0; i < get_claim_size; i++)
  {
    if (data[i] == '\r')
    {
      LOG_DBG("Found \\r at index %d", i);
      ret_val = i;
      break;
    }
  }
  if (buf_has_wrapped)
  {
    uint32_t get_claim_size2 =
        ring_buf_get_claim(buf, &data_remain, get_size - get_claim_size);
    for (uint32_t i = 0; i < get_claim_size2; i++)
    {
      if (data_remain[i] == '\r')
      {
        LOG_DBG("Found \\r at index %d", -1 * i);
        ret_val = -1 * i;
        break;
      }
    }
  }
  if (ring_buf_get_finish(buf, 0) != 0)
  {
    LOG_ERR("Failed to free ring buffer");
  }
  return ret_val;
}

int start_can_device(const struct device *can_dev)
{
  int err = 0;
  err = can_start(can_dev);
  if (err != 0)
  {
    LOG_ERR("Error starting CAN controller (err %d)", err);
  }

  return err;
}

int stop_can_device(const struct device *can_dev)
{
  int err = 0;
  err = can_stop(can_dev);
  if (err != 0)
  {
    LOG_ERR("Error stopping CAN controller (err %d)", err);
  }
  return err;
}

int set_bitrate(const struct device *can_dev, uint8_t bitrate_code)
{
  int err;
  struct can_timing timing;
  uint32_t bitrate_k;
  // If the sample point is set to 0, this function defaults to a sample point
  // of 75.0% for bitrates over 800 kbit/s, 80.0% for bitrates over 500 kbit/s,
  // and 87.5% for all other bitrates.
  switch (bitrate_code)
  {
  case '0':
    bitrate_k = 10;
    break;
  case '1':
    bitrate_k = 20;
    break;
  case '2':
    bitrate_k = 50;
    break;
  case '3':
    bitrate_k = 100;
    break;
  case '4':
    bitrate_k = 125;
    break;
  case '5':
    bitrate_k = 200;
    break;
  case '6':
    bitrate_k = 250;
    break;
  case '7':
    bitrate_k = 500;
    break;
  case '8':
    bitrate_k = 1000;
    break;
  default:
    err = -EINVAL;
    LOG_ERR("Invalid bitrate code: %d", bitrate_code);
    goto set_bitrate_return;
  }
  err = can_calc_timing(can_dev, &timing, bitrate_k * 1000, 0);
  if (err > 0)
  {
    LOG_INF("Sample-Point error: %d", err);
  }

  if (err < 0)
  {
    LOG_ERR("Failed to calc timing for speed %d", bitrate_k * 1000);
    goto set_bitrate_return;
  }
  err = can_set_timing(can_dev, &timing);
  if (err != 0)
  {
    LOG_ERR("Failed to set timing");
    goto set_bitrate_return;
  }

set_bitrate_return:
  return err;
}

struct uart_message can_frame_to_uart_message(const struct can_frame *frame,
                                              int filter_id)
{
  struct uart_message message;
  size_t offset = 0;
  int err = 0;
  if (frame->flags & CAN_FRAME_IDE)
  {
    message.buffer[offset++] = 'R';
    err = snprintf(&message.buffer[offset], 9, "%08x", frame->id);
    __ASSERT(err == 8, "Failed to write CAN ID to UART message buffer");
    offset += 8;
  }
  else
  {
    message.buffer[offset++] = 'r';
    err = snprintf(&message.buffer[offset], 4, "%03x", frame->id);
    __ASSERT(err == 3, "Failed to write CAN ID to UART message buffer");
    offset += 3;
  }

  err = snprintf(&message.buffer[offset], 3, "%02x", filter_id);
  __ASSERT(err == 2, "Failed to write CAN filter ID to UART message buffer");
  offset += 2;

  err = snprintf(&message.buffer[offset], 2, "%01x",
                 (uint8_t)(frame->dlc & 0x0F));
  __ASSERT(err == 1, "Failed to write CAN DLC to UART message buffer");
  offset += 1;

  for (size_t i = 0; i < frame->dlc; i++)
  {
    err = snprintf(&message.buffer[offset], 3, "%02x", frame->data[i]);
    __ASSERT(err == 2, "Failed to write CAN Data to UART message buffer");
    offset += 2;
  }
  message.buffer[offset++] = COMMAND_RESPONSE_OKAY[0];
  message.buffer_size = offset;
  __ASSERT(offset <= MAX_UART_CAN_FRAME, "UART message buffer overflow");
  return message;
}

int send_can_message_no_wait(const struct device *can_dev, uint32_t addr,
                             const uint8_t data[], uint8_t data_size,
                             bool is_extended_id, bool is_rtr)
{
  int err = 0;

  if (data_size > CAN_MAX_DLEN)
  {
    LOG_ERR("Data size is too large");
    err = -1;
    goto send_can_message_return;
  }
  struct can_frame frame;
  frame.id = addr;
  frame.dlc = data_size;
  frame.flags = 0;
  frame.reserved = 0;
  memcpy(frame.data, data, data_size);

  if (is_extended_id)
  {
    frame.flags |= CAN_FRAME_IDE;
  }

  if (is_rtr)
  {
    frame.flags |= CAN_FRAME_RTR;
  }

  LOG_DBG("babbling on %s with %s (%d-bit) CAN ID 0x%0*x, RTR %d, CAN FD %d "
          "with data of size %d and buffer contains",
          can_dev->name,
          (frame.flags & CAN_FRAME_IDE) != 0 ? "extended" : "standard",
          (frame.flags & CAN_FRAME_IDE) != 0 ? 29 : 11,
          (frame.flags & CAN_FRAME_IDE) != 0 ? 8 : 3, frame.id,
          (frame.flags & CAN_FRAME_RTR) != 0 ? 1 : 0,
          (frame.flags & CAN_FRAME_FDF) != 0 ? 1 : 0, data_size);
  LOG_HEXDUMP_DBG(data, data_size, "My CAN Data Buffer:%s");

  err = can_send(can_dev, &frame, K_NO_WAIT, can_tx_callback,
                 is_extended_id ? "T" : "t");
  if (err != 0)
  {
    LOG_ERR("Failed to enqueue CAN frame (err %d)", err);
    // TODO (Matthew): What could cause CAN to fail
    goto send_can_message_return;
  }

send_can_message_return:
  return err;
}

int add_can_filter(const struct device *can_dev, uint32_t filter_id,
                   uint32_t filter_mask, bool is_extended_id)
{
  const struct can_filter filter = {
      .id = filter_id,
      .mask = filter_mask,
      .flags = is_extended_id ? CAN_FILTER_IDE : 0,

  };

  int *temp_filter_id_ptr;
  int err = k_mem_slab_alloc(&filter_id_list_slab, (void **)&temp_filter_id_ptr,
                             K_NO_WAIT);
  if (err != 0)
  {
    LOG_ERR("Failed to allocate filter (err: %d)", err);
    goto add_can_filter_return;
  }

  err =
      can_add_rx_filter(can_dev, can_rx_callback, temp_filter_id_ptr, &filter);

  if (err < 0)
  {
    k_mem_slab_free(&filter_id_list_slab, temp_filter_id_ptr);
    LOG_ERR("Failed to bind CAN hardware filter (err: %d)", err);
    goto add_can_filter_return;
  }
  *temp_filter_id_ptr = err;
  filter_ids_ptr_map[err] = temp_filter_id_ptr;
add_can_filter_return:
  return err;
}

int remove_can_filter(const struct device *can_dev, int filter_id)
{
  int err = 0;
  if (filter_id >=
      (CONFIG_CAN_MAX_STD_ID_FILTERS + CONFIG_CAN_MAX_EXT_ID_FILTERS))
  {
    LOG_ERR("Invalid CAN filter ID");
    err = -1;
    goto remove_can_filter_return;
  }

  if (filter_ids_ptr_map[filter_id] == NULL)
  {
    LOG_ERR("Invalid CAN filter ID");
    err = -1;
    goto remove_can_filter_return;
  }

  can_remove_rx_filter(can_dev, filter_id);
  k_mem_slab_free(&filter_id_list_slab, filter_ids_ptr_map[filter_id]);
  filter_ids_ptr_map[filter_id] = NULL;
remove_can_filter_return:
  return err;
}

void clear_buf_till_r(struct ring_buf *buf)
{
  uint32_t buf_size = ring_buf_size_get(buf);
  for (uint32_t i = 0; i < buf_size; i++)
  {
    if (ring_buf_get_char(buf) == '\r')
    {
      break;
    }
  }
}
```
